# STM32G061 register map
File version: 1.4
CPU: CM0 r0p1, little endian, MPU, no FPU, 2 interrupt priority bits
Registers are 32-bit, read-write, reset 0x0 unless marked. A register's access mark holds for its fields unless they carry their own. Offsets are from the block's base; [hi:lo] are bit positions; {n}, {i} and the like mark numbered series; 'fields as' and 'values as' point back to an identical list.

## ADC — ADC address block description
Base 0x40012400
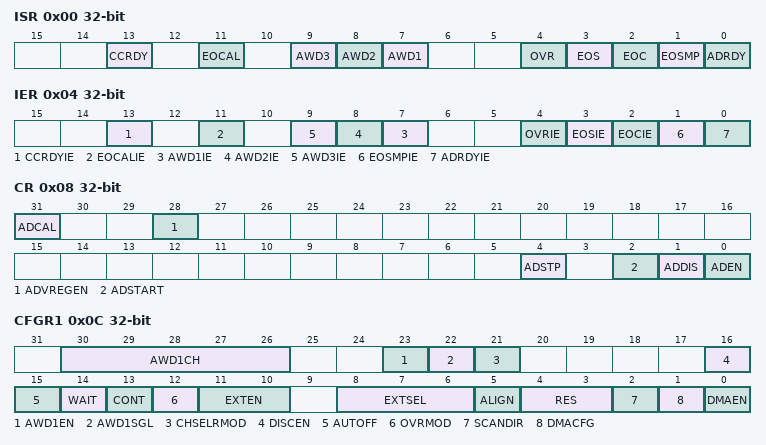
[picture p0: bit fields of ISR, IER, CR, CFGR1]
0x00 ISR — ADC interrupt and status register
  [13] CCRDY write-1-clears — Channel Configuration Ready flag This flag bit is set by hardware when the channel configuration is applied after programming to ADC_CHSELR register or changing CHSELRMOD or SCANDIR. It is cleared by software by programming it to it. Note: When the software configures the channels (by programming ADC_CHSELR or changing CHSELRMOD or SCANDIR), it must wait until the CCRDY flag rises before configuring again or starting conversions, otherwise the new configuration (or the START bit) is ignored. Once the flag is asserted, if the software needs to configure again the channels, it must clear the CCRDY flag before proceeding with a new configuration.
    on read: 0=NotComplete (Channel configuration update not applied); 1=Complete (Channel configuration update is applied) | on write: 1=Clear the channel configuration flag
  [11] EOCAL write-1-clears — End Of Calibration flag This bit is set by hardware when calibration is complete. It is cleared by software writing 1 to it.
    on read: 0=NotComplete (Calibration is not complete); 1=Complete (Calibration complete) | on write: 1=Clear the calibration flag
  [n+6] AWD{n} (n=1..3) write-1-clears — Analog watchdog {n} flag
    on read: 0=NoEvent (No analog watchdog event occurred); 1=Event (Analog watchdog event occurred) | on write: 1=Clear the analog watchdog event flag
  [4] OVR write-1-clears — ADC overrun This bit is set by hardware when an overrun occurs, meaning that a new conversion has complete while the EOC flag was already set. It is cleared by software writing 1 to it.
    on read: 0=No overrun occurred; 1=Overrun occurred | on write: 1=Clear the overrun flag
  [3] EOS write-1-clears — End of sequence flag This bit is set by hardware at the end of the conversion of a sequence of channels selected by the CHSEL bits. It is cleared by software writing 1 to it.
    on read: 0=NotComplete (Conversion sequence is not complete); 1=Complete (Conversion sequence complete) | on write: 1=Clear the conversion sequence flag
  [2] EOC write-1-clears — End of conversion flag This bit is set by hardware at the end of each conversion of a channel when a new data result is available in the ADC_DR register. It is cleared by software writing 1 to it or by reading the ADC_DR register.
    on read: 0=NotComplete (Channel conversion is not complete); 1=Complete (Channel conversion complete) | on write: 1=Clear the channel conversion flag
  [1] EOSMP write-1-clears — End of sampling flag This bit is set by hardware during the conversion, at the end of the sampling phase.It is cleared by software by programming it to '1'.
    on read: 0=NotAtEnd (Not at the end of the samplings phase); 1=AtEnd (End of sampling phase reached) | on write: 1=Clear the sampling phase flag
  [0] ADRDY write-1-clears — ADC ready This bit is set by hardware after the ADC has been enabled (ADEN = 1) and when the ADC reaches a state where it is ready to accept conversion requests. It is cleared by software writing 1 to it.
    on read: 0=NotReady (ADC not yet ready to start conversion); 1=Ready (ADC ready to start conversion) | on write: 1=Clear the ADC ready flag
0x04 IER — ADC interrupt enable register
  [13] CCRDYIE — Channel Configuration Ready Interrupt enable This bit is set and cleared by software to enable/disable the channel configuration ready interrupt. Note: The software is allowed to write this bit only when ADSTART bit is cleared to 0 (this ensures that no conversion is ongoing).
    0=Disabled (Channel configuration ready interrupt disabled); 1=Enabled (Channel configuration ready interrupt enabled)
  [11] EOCALIE — End of calibration interrupt enable This bit is set and cleared by software to enable/disable the end of calibration interrupt. Note: The software is allowed to write this bit only when ADSTART bit is cleared to 0 (this ensures that no conversion is ongoing).
    0=Disabled (End of calibration interrupt disabled); 1=Enabled (End of calibration interrupt enabled)
  [n+6] AWD{n}IE (n=1..3) — Analog watchdog {n} interrupt enable
    0=Disabled (Analog watchdog interrupt disabled); 1=Enabled (Analog watchdog interrupt enabled)
  [4] OVRIE — Overrun interrupt enable This bit is set and cleared by software to enable/disable the overrun interrupt. Note: The software is allowed to write this bit only when ADSTART bit is cleared to 0 (this ensures that no conversion is ongoing).
    0=Disabled (Overrun interrupt disabled); 1=Enabled (Overrun interrupt enabled. An interrupt is generated when the OVR bit is set.)
  [3] EOSIE — End of conversion sequence interrupt enable This bit is set and cleared by software to enable/disable the end of sequence of conversions interrupt. Note: The software is allowed to write this bit only when ADSTART bit is cleared to 0 (this ensures that no conversion is ongoing).
    0=Disabled (EOS interrupt disabled); 1=Enabled (EOS interrupt enabled. An interrupt is generated when the EOS bit is set.)
  [2] EOCIE — End of conversion interrupt enable This bit is set and cleared by software to enable/disable the end of conversion interrupt. Note: The software is allowed to write this bit only when ADSTART bit is cleared to 0 (this ensures that no conversion is ongoing).
    0=Disabled (EOC interrupt disabled); 1=Enabled (EOC interrupt enabled. An interrupt is generated when the EOC bit is set.)
  [1] EOSMPIE — End of sampling flag interrupt enable This bit is set and cleared by software to enable/disable the end of the sampling phase interrupt. Note: The software is allowed to write this bit only when ADSTART bit is cleared to 0 (this ensures that no conversion is ongoing).
    0=Disabled (EOSMP interrupt disabled); 1=Enabled (EOSMP interrupt enabled. An interrupt is generated when the EOSMP bit is set.)
  [0] ADRDYIE — ADC ready interrupt enable This bit is set and cleared by software to enable/disable the ADC Ready interrupt. Note: The software is allowed to write this bit only when ADSTART bit is cleared to 0 (this ensures that no conversion is ongoing).
    0=Disabled (ADRDY interrupt disabled); 1=Enabled (ADRDY interrupt enabled. An interrupt is generated when the ADRDY bit is set.)
0x08 CR — ADC control register
  [31] ADCAL write-1-sets — ADC calibration This bit is set by software to start the calibration of the ADC. It is cleared by hardware after calibration is complete. Note: The software is allowed to set ADCAL only when the ADC is disabled (ADCAL=0, ADSTART=0, ADSTP=0, ADDIS=0 and ADEN=0). The software is allowed to update the calibration factor by writing ADC_CALFACT only when ADEN=1 and ADSTART=0 (ADC enabled and no conversion is ongoing).
    on read: 0=NotCalibrating (ADC calibration either not yet performed or completed); 1=Calibrating (ADC calibration in progress) | on write: 1=StartCalibration (Start the ADC calibration sequence)
  [28] ADVREGEN — ADC Voltage Regulator Enable This bit is set by software, to enable the ADC internal voltage regulator. The voltage regulator output is available after tADCVREG_SETUP. It is cleared by software to disable the voltage regulator. It can be cleared only if ADEN is et to 0. Note: The software is allowed to program this bit field only when the ADC is disabled (ADCAL = 0, ADSTART = 0, ADSTP = 0, ADDIS = 0 and ADEN = 0).
    0=Disabled (ADC voltage regulator disabled); 1=Enabled (ADC voltage regulator enabled)
  [4] ADSTP write-1-sets — ADC stop conversion command This bit is set by software to stop and discard an ongoing conversion (ADSTP Command). It is cleared by hardware when the conversion is effectively discarded and the ADC is ready to accept a new start conversion command. Note: Setting ADSTP to '1' is only effective when ADSTART = 1 and ADDIS = 0 (ADC is enabled and may be converting and there is no pending request to disable the ADC)
    on read: 0=NotStopping (No stop command active); 1=Stopping (ADC stopping conversion) | on write: 1=StopConversion (Stop the active conversion)
  [2] ADSTART write-1-sets — ADC start conversion command This bit is set by software to start ADC conversion. Depending on the EXTEN [1:0] configuration bits, a conversion either starts immediately (software trigger configuration) or once a hardware trigger event occurs (hardware trigger configuration). It is cleared by hardware: In single conversion mode (CONT = 0, DISCEN = 0), when software trigger is selected (EXTEN = 00): at the assertion of the end of Conversion Sequence (EOS) flag. In discontinuous conversion mode(CONT = 0, DISCEN = 1), when the software trigger is selected (EXTEN = 00): at the assertion of the end of Conversion (EOC) flag. In all other cases: after the execution of the ADSTP command, at the same time as the ADSTP bit is cleared by hardware. Note: The software is allowed to set ADSTART only when ADEN = 1 and ADDIS = 0 (ADC is enabled and there is no pending request to disable the ADC). After writing to ADC_CHSELR register or changing CHSELRMOD or SCANDIRW, it is mandatory to wait until CCRDY flag is asserted before setting ADSTART, otherwise, the value written to ADSTART is ignored.
    on read: 0=NotActive (No conversion ongoing); 1=Active (ADC operating and may be converting) | on write: 1=StartConversion (Start the ADC conversion (may be delayed for hardware triggers))
  [1] ADDIS write-1-sets — ADC disable command This bit is set by software to disable the ADC (ADDIS command) and put it into power-down state (OFF state). It is cleared by hardware once the ADC is effectively disabled (ADEN is also cleared by hardware at this time). Note: Setting ADDIS to '1' is only effective when ADEN = 1 and ADSTART = 0 (which ensures that no conversion is ongoing)
    on read: 0=NotDisabling (No disable command active); 1=Disabling (ADC disabling) | on write: 1=Disable the ADC
  [0] ADEN write-1-sets — ADC enable command This bit is set by software to enable the ADC. The ADC is effectively ready to operate once the ADRDY flag has been set. It is cleared by hardware when the ADC is disabled, after the execution of the ADDIS command. Note: The software is allowed to set ADEN only when all bits of ADC_CR registers are 0 (ADCAL = 0, ADSTP=0, ADSTART=0, ADDIS=0 and ADEN=0)
    on read: 0=Disabled (ADC disabled); 1=Enabled (ADC enabled) | on write: 1=Enabled (Enable the ADC)
0x0C CFGR1 — ADC configuration register 1
  [30:26] AWD1CH range 0..17 — Analog watchdog channel selection These bits are set and cleared by software. They select the input channel to be guarded by the analog watchdog. ..... Others: Reserved Note: The channel selected by the AWDCH[4:0] bits must be also set into the CHSELR register. The software is allowed to write this bit only when ADSTART bit is cleared to 0 (this ensures that no conversion is ongoing).
  [23] AWD1EN — Analog watchdog enable This bit is set and cleared by software. Note: The software is allowed to write this bit only when ADSTART bit is cleared to 0 (this ensures that no conversion is ongoing).
    0=Disabled (Analog watchdog 1 disabled); 1=Enabled (Analog watchdog 1 enabled)
  [22] AWD1SGL — Enable the watchdog on a single channel or on all channels This bit is set and cleared by software to enable the analog watchdog on the channel identified by the AWDCH[4:0] bits or on all the channels Note: The software is allowed to write this bit only when ADSTART bit is cleared to 0 (this ensures that no conversion is ongoing).
    0=AllChannels (Analog watchdog 1 enabled on all channels); 1=SingleChannel (Analog watchdog 1 enabled on a single channel)
  [21] CHSELRMOD — Mode selection of the ADC_CHSELR register This bit is set and cleared by software to control the ADC_CHSELR feature: Note: The software is allowed to write this bit only when ADSTART bit is cleared to 0 (this ensures that no conversion is ongoing). If CCRDY is not yet asserted after channel configuration (writing ADC_CHSELR register or changing CHSELRMOD or SCANDIR), the value written to this bit is ignored.
    0=BitPerInput (Each bit of the ADC_CHSELR register enables an input); 1=Sequence (ADC_CHSELR register is able to sequence up to 8 channels)
  [16] DISCEN — Discontinuous mode This bit is set and cleared by software to enable/disable discontinuous mode. Note: It is not possible to have both discontinuous mode and continuous mode enabled: it is forbidden to set both bits DISCEN=1 and CONT=1. The software is allowed to write this bit only when ADSTART bit is cleared to 0 (this ensures that no conversion is ongoing).
    0=Disabled (Discontinuous mode disabled); 1=Enabled (Discontinuous mode enabled)
  [15] AUTOFF — Auto-off mode This bit is set and cleared by software to enable/disable auto-off mode.. Note: The software is allowed to write this bit only when ADSTART bit is cleared to 0 (this ensures that no conversion is ongoing).
    0=Disabled (Auto-off mode disabled); 1=Enabled (Auto-off mode enabled)
  [14] WAIT — Wait conversion mode This bit is set and cleared by software to enable/disable wait conversion mode.. Note: The software is allowed to write this bit only when ADSTART bit is cleared to 0 (this ensures that no conversion is ongoing).
    0=Disabled (Wait conversion mode off); 1=Enabled (Wait conversion mode on)
  [13] CONT — Single / continuous conversion mode This bit is set and cleared by software. If it is set, conversion takes place continuously until it is cleared. Note: It is not possible to have both discontinuous mode and continuous mode enabled: it is forbidden to set both bits DISCEN=1 and CONT=1. The software is allowed to write this bit only when ADSTART bit is cleared to 0 (this ensures that no conversion is ongoing).
    0=Single conversion mode; 1=Continuous conversion mode
  [12] OVRMOD — Overrun management mode This bit is set and cleared by software and configure the way data overruns are managed. Note: The software is allowed to write this bit only when ADSTART bit is cleared to 0 (this ensures that no conversion is ongoing).
    0=Preserve (ADC_DR register is preserved with the old data when an overrun is detected); 1=Overwrite (ADC_DR register is overwritten with the last conversion result when an overrun is detected)
  [11:10] EXTEN — External trigger enable and polarity selection These bits are set and cleared by software to select the external trigger polarity and enable the trigger. Note: The software is allowed to write this bit only when ADSTART bit is cleared to 0 (this ensures that no conversion is ongoing).
    0=Disabled (Hardware trigger detection disabled); 1=RisingEdge (Hardware trigger detection on the rising edge); 2=FallingEdge (Hardware trigger detection on the falling edge); 3=BothEdges (Hardware trigger detection on both the rising and falling edges)
  [8:6] EXTSEL — External trigger selection These bits select the external event used to trigger the start of conversion (refer to External triggers for details): Note: The software is allowed to write this bit only when ADSTART bit is cleared to 0 (this ensures that no conversion is ongoing).
    0=TIM1_TRGO2 (Timer 1 TRGO 2 event); 1=TIM1_CC4 (Timer 1 CC4 event); 2=TIM2_TRGO (Timer 2 TRGO event); 3=TIM3_TRGO (Timer 3 TRGO event); 4=TIM15_TRGO (Timer 15 TRGO event); 5=TIM6_TRGO (Timer 6 TRGO event); 6=TIM4_TRGO (Timer 4 TRGO event); 7=EXTI11 (EXTI line 11 event)
  [5] ALIGN — Data alignment This bit is set and cleared by software to select right or left alignment. Refer to Data alignment and resolution (oversampling disabled: OVSE = 0) on page389 Note: The software is allowed to write this bit only when ADSTART bit is cleared to 0 (this ensures that no conversion is ongoing).
    0=Right alignment; 1=Left alignment
  [4:3] RES — Data resolution These bits are written by software to select the resolution of the conversion. Note: The software is allowed to write these bits only when ADEN=0.
    0=Bits12 (12 bits); 1=Bits10 (10 bits); 2=Bits8 (8 bits); 3=Bits6 (6 bits)
  [2] SCANDIR — Scan sequence direction This bit is set and cleared by software to select the direction in which the channels is scanned in the sequence. It is effective only if CHSELMOD bit is cleared to 0. Note: The software is allowed to write this bit only when ADSTART bit is cleared to 0 (this ensures that no conversion is ongoing). If CCRDY is not yet asserted after channel configuration (writing ADC_CHSELR register or changing CHSELRMOD or SCANDIR), the value written to this bit is ignored.
    0=Upward scan (from CHSEL0 to CHSEL17); 1=Backward scan (from CHSEL17 to CHSEL0)
  [1] DMACFG — Direct memory access configuration This bit is set and cleared by software to select between two DMA modes of operation and is effective only when DMAEN=1. For more details, refer to page391 Note: The software is allowed to write this bit only when ADSTART bit is cleared to 0 (this ensures that no conversion is ongoing).
    0=OneShot (DMA one shot mode selected); 1=Circular (DMA circular mode selected)
  [0] DMAEN — Direct memory access enable This bit is set and cleared by software to enable the generation of DMA requests. This allows the DMA controller to be used to manage automatically the converted data. For more details, refer to . Note: The software is allowed to write this bit only when ADSTART bit is cleared to 0 (this ensures that no conversion is ongoing).
    0=Disabled (DMA disabled); 1=Enabled (DMA enabled)
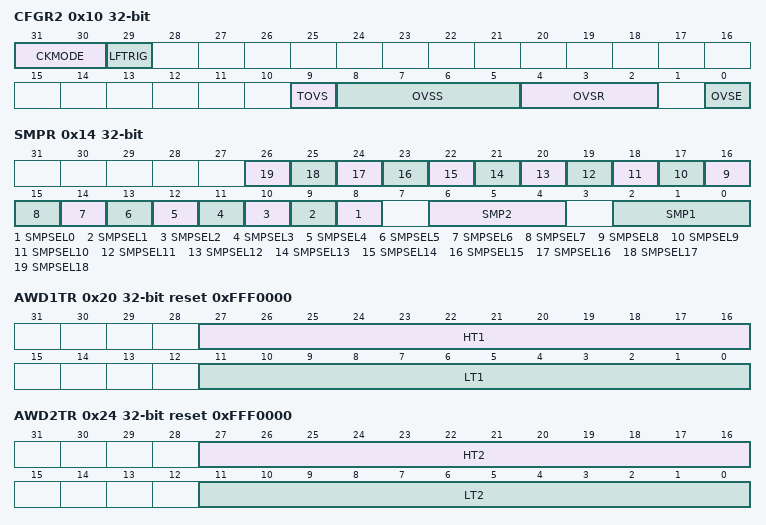
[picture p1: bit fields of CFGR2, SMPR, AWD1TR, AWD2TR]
0x10 CFGR2 — ADC configuration register 2
  [31:30] CKMODE — ADC clock mode These bits are set and cleared by software to define how the analog ADC is clocked: In all synchronous clock modes, there is no jitter in the delay from a timer trigger to the start of a conversion. Note: The software is allowed to write these bits only when the ADC is disabled (ADCAL=0, ADSTART=0, ADSTP=0, ADDIS=0 and ADEN=0).
    0=ADCLK (ADCCLK (Asynchronous clock mode)); 1=PCLK_Div2 (PCLK/2 (Synchronous clock mode)); 2=PCLK_Div4 (PCLK/4 (Synchronous clock mode)); 3=PCLK (PCLK (Synchronous clock mode))
  [29] LFTRIG — Low frequency trigger mode enable This bit is set and cleared by software. Note: The software is allowed to write this bit only when ADSTART bit is cleared to 0 (this ensures that no conversion is ongoing).
    0=Disabled (Low Frequency Trigger Mode disabled); 1=Enabled (Low Frequency Trigger Mode enabled)
  [9] TOVS — Triggered Oversampling This bit is set and cleared by software. Note: The software is allowed to write this bit only when ADSTART=0 (which ensures that no conversion is ongoing).
    0=TriggerAll (All oversampled conversions for a channel are done consecutively after a trigger); 1=TriggerEach (Each oversampled conversion for a channel needs a trigger)
  [8:5] OVSS — Oversampling shift This bit is set and cleared by software. Others: Reserved Note: The software is allowed to write this bit only when ADSTART=0 (which ensures that no conversion is ongoing).
    0=NoShift; 1=Shift 1-bit; {v}=Shift {v}-bits (v=2..8)
  [4:2] OVSR — Oversampling ratio This bit filed defines the number of oversampling ratio. Note: The software is allowed to write this bit only when ADSTART=0 (which ensures that no conversion is ongoing).
    0=Mul2 (2x); 1=Mul4 (4x); 2=Mul8 (8x); 3=Mul16 (16x); 4=Mul32 (32x); 5=Mul64 (64x); 6=Mul128 (128x); 7=Mul256 (256x)
  [0] OVSE — Oversampler Enable This bit is set and cleared by software. Note: Software is allowed to write this bit only when ADSTART=0 (which ensures that no conversion is ongoing).
    0=Disabled (Oversampler disabled); 1=Enabled (Oversampler enabled)
0x14 SMPR — ADC sampling time register
  [n+8] SMPSEL{n} (n=0..18) — Channel-{n} sampling time selection
    0=Smp1 (Sampling time of CHANNELx use the setting of SMP1 register); 1=Smp2 (Sampling time of CHANNELx use the setting of SMP2 register)
  [4n-2:4n-4] SMP{n} (n=1..2) — Sampling time selection {n}
    0=Cycles1_5 (1.5 ADC clock cycles); 1=Cycles3_5 (3.5 ADC clock cycles); 2=Cycles7_5 (7.5 ADC clock cycles); 3=Cycles12_5 (12.5 ADC clock cycles); 4=Cycles19_5 (19.5 ADC clock cycles); 5=Cycles39_5 (39.5 ADC clock cycles); 6=Cycles79_5 (79.5 ADC clock cycles); 7=Cycles160_5 (160.5 ADC clock cycles)
0x20 AWD1TR reset 0xFFF0000 — ADC watchdog threshold register
  [27:16] HT1 — Analog watchdog 1 higher threshold These bits are written by software to define the higher threshold for the analog watchdog. Refer to ADC_AWDxTR) on page395.
  [11:0] LT1 — Analog watchdog 1 lower threshold These bits are written by software to define the lower threshold for the analog watchdog. Refer to ADC_AWDxTR) on page395.
0x24 AWD2TR reset 0xFFF0000 — ADC watchdog threshold register
  [27:16] HT2 — Analog watchdog 2 higher threshold These bits are written by software to define the higher threshold for the analog watchdog. Refer to ADC_AWDxTR) on page395.
  [11:0] LT2 — Analog watchdog 2 lower threshold These bits are written by software to define the lower threshold for the analog watchdog. Refer to ADC_AWDxTR) on page395.
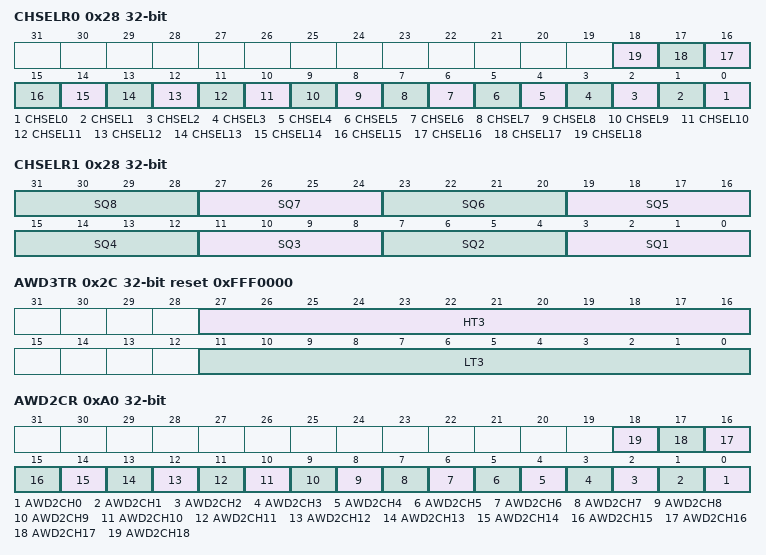
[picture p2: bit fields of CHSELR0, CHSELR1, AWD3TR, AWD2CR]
0x28 CHSELR0 — ADC channel selection register
  [n] CHSEL{n} (n=0..18) — Channel-{n} selection
    0=NotSelected (Input Channel is not selected for conversion); 1=Selected (Input Channel is selected for conversion)
0x28 CHSELR1 (alternate view of CHSELR0) — ADC channel selection register
  [4n-1:4n-4] SQ{n} (n=1..8) — {n} conversion of the sequence
    {v}=Ch{v} (Channel {v} selected for the Nth conversion) (v=0..14); 15=EOS (End of sequence)
0x2C AWD3TR reset 0xFFF0000 — ADC watchdog threshold register
  [27:16] HT3 — Analog watchdog 3 higher threshold These bits are written by software to define the higher threshold for the analog watchdog. Refer to ADC_AWDxTR) on page395.
  [11:0] LT3 — Analog watchdog 3lower threshold These bits are written by software to define the lower threshold for the analog watchdog. Refer to ADC_AWDxTR) on page395.
0x40 DR ro — ADC data register
  [15:0] DATA — Converted data These bits are read-only. They contain the conversion result from the last converted channel. The data are left- or right-aligned as shown in OVSE = 0) on page389. Just after a calibration is complete, DATA[6:0] contains the calibration factor.
0xA0 AWD2CR — ADC Analog Watchdog 2 Configuration register
  [n] AWD2CH{n} (n=0..18) — Analog watchdog channel selection These bits are set and cleared by software. They enable and select the input channels to be guarded by analog watchdog 2 (AWD2). Note: The channels selected through ADC_AWD2CR must be also configured into the ADC_CHSELR registers. Refer to SQ8[3:0] for a definition of channel selection. The software is allowed to write this bit only when ADSTART=0 (which ensures that no conversion is ongoing).
    0=NotMonitored (ADC analog channel-x is not monitored by AWD2); 1=Monitored (ADC analog channel-x is monitored by AWD2)
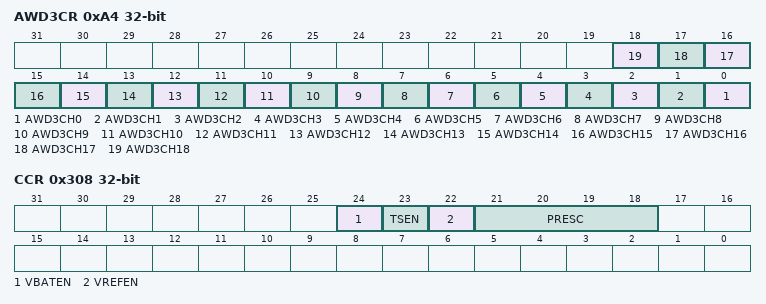
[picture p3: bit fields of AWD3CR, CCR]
0xA4 AWD3CR — ADC Analog Watchdog 3 Configuration register
  [n] AWD3CH{n} (n=0..18) — Analog watchdog channel selection These bits are set and cleared by software. They enable and select the input channels to be guarded by analog watchdog 3 (AWD3). Note: The channels selected through ADC_AWD3CR must be also configured into the ADC_CHSELR registers. Refer to SQ8[3:0] for a definition of channel selection. The software is allowed to write this bit only when ADSTART=0 (which ensures that no conversion is ongoing).
    0=NotMonitored (ADC analog channel-x is not monitored by AWD3); 1=Monitored (ADC analog channel-x is monitored by AWD3)
0xB4 CALFACT — ADC Calibration factor
  [6:0] CALFACT — Calibration factor These bits are written by hardware or by software. Once a calibration is complete,they are updated by hardware with the calibration factors. Software can write these bits with a new calibration factor. If the new calibration factor is different from the current one stored into the analog ADC, it is then applied once a new calibration is launched. Just after a calibration is complete, DATA[6:0] contains the calibration factor. Note: Software can write these bits only when ADEN=1 (ADC is enabled and no calibration is ongoing and no conversion is ongoing). Refer to SQ8[3:0] for a definition of channel selection.
0x308 CCR — ADC common configuration register
  [24] VBATEN — VBAT enable This bit is set and cleared by software to enable/disable the VBAT channel. Note: The software is allowed to write this bit only when ADSTART=0 (which ensures that no conversion is ongoing)
    0=Disabled (The selected ADC channel disabled); 1=Enabled (The selected ADC channel enabled)
  [23] TSEN — Temperature sensor enable This bit is set and cleared by software to enable/disable the temperature sensor. Note: Software is allowed to write this bit only when ADSTART=0 (which ensures that no conversion is ongoing).
    values as VBATEN
  [22] VREFEN — VREFINT enable This bit is set and cleared by software to enable/disable the VREFINT. Note: Software is allowed to write this bit only when ADSTART=0 (which ensures that no conversion is ongoing).
    values as VBATEN
  [21:18] PRESC — ADC prescaler Set and cleared by software to select the frequency of the clock to the ADC. Other: Reserved Note: Software is allowed to write these bits only when the ADC is disabled (ADCAL=0, ADSTART=0, ADSTP=0, ADDIS=0 and ADEN=0).
    0=Div1 (Input ADC clock not divided); 1=Div2 (Input ADC clock divided by 2); 2=Div4 (Input ADC clock divided by 4); 3=Div6 (Input ADC clock divided by 6); 4=Div8 (Input ADC clock divided by 8); 5=Div10 (Input ADC clock divided by 10); 6=Div12 (Input ADC clock divided by 12); 7=Div16 (Input ADC clock divided by 16); 8=Div32 (Input ADC clock divided by 32); 9=Div64 (Input ADC clock divided by 64); 10=Div128 (Input ADC clock divided by 128); 11=Div256 (Input ADC clock divided by 256)
